# ETHSW register map
Registers are 32-bit, read-only, no defined reset value unless marked. A register's access mark holds for its fields unless they carry their own. Addresses are absolute; registers are grouped by the start of their names; [hi:lo] are bit positions; {n}, {i} and the like mark numbered series.

## etherStatsOversizePkts
{0x440508BC+0x400*i} etherStatsOversizePkts_P{i} (i=0..4)

## etherStatsPkts64Octets
{0x440508C0+0x400*i} etherStatsPkts64Octets_P{i} (i=0..4)

## etherStatsPkts65to127Octets
{0x440508C4+0x400*i} etherStatsPkts65to127Octets_P{i} (i=0..4)

## etherStatsPkts128to255Octets
{0x440508C8+0x400*i} etherStatsPkts128to255Octets_P{i} (i=0..4)

## etherStatsPkts256to511Octets
{0x440508CC+0x400*i} etherStatsPkts256to511Octets_P{i} (i=0..4)

## etherStatsPkts512to1023Octets
{0x440508D0+0x400*i} etherStatsPkts512to1023Octets_P{i} (i=0..4)

## etherStatsPkts1024to1518Octets
{0x440508D4+0x400*i} etherStatsPkts1024to1518Octets_P{i} (i=0..4)

## etherStatsPkts1519toXOctets
{0x440508D8+0x400*i} etherStatsPkts1519toXOctets_P{i} (i=0..4)

## etherStatsJabbers
{0x440508DC+0x400*i} etherStatsJabbers_P{i} (i=0..4)

## etherStatsFragments
{0x440508E0+0x400*i} etherStatsFragments_P{i} (i=0..4)

## VLANReceivedOK
{0x440508E8+0x400*i} VLANReceivedOK_P{i} (i=0..4)

## VLANTransmittedOK
{0x440508F4+0x400*i} VLANTransmittedOK_P{i} (i=0..4)

## FramesRetransmitted
{0x440508F8+0x400*i} FramesRetransmitted_P{i} (i=0..4)

## STATS
{0x44050900+0x400*i} STATS_HIWORD_P{i} (i=0..4)
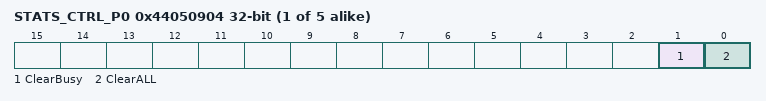
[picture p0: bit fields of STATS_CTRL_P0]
{0x44050904+0x400*i} STATS_CTRL_P{i} access not given (i=0..4)
  [1] ClearBusy, [0] ClearALL
{0x44050908+0x400*i} STATS_CLEAR_VALUELO_P{i} (i=0..4)
{0x4405090C+0x400*i} STATS_CLEAR_VALUEHI_P{i} (i=0..4)

## aDeferred
{0x44050910+0x400*i} aDeferred_P{i} (i=0..4)

## aMultipleCollisions
{0x44050914+0x400*i} aMultipleCollisions_P{i} (i=0..4)

## aSingleCollisions
{0x44050918+0x400*i} aSingleCollisions_P{i} (i=0..4)

## aLateCollisions
{0x4405091C+0x400*i} aLateCollisions_P{i} (i=0..4)

## aExcessiveCollisions
{0x44050920+0x400*i} aExcessiveCollisions_P{i} (i=0..4)

## aCarrierSenseErrors
{0x44050924+0x400*i} aCarrierSenseErrors_P{i} (i=0..4)

## DLR
0x44053C08 DLR_ETH_TYP access not given
  [15:0] DLR_ETH_TYP
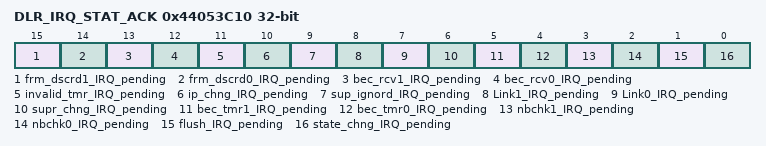
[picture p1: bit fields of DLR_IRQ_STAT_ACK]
0x44053C10 DLR_IRQ_STAT_ACK access not given
  [15] frm_dscrd1_IRQ_pending, [14] frm_dscrd0_IRQ_pending, [13] bec_rcv1_IRQ_pending, [12] bec_rcv0_IRQ_pending, [11] invalid_tmr_IRQ_pending, [10] ip_chng_IRQ_pending, [9] sup_ignord_IRQ_pending, [8] Link1_IRQ_pending, [7] Link0_IRQ_pending, [6] supr_chng_IRQ_pending, [5] bec_tmr1_IRQ_pending, [4] bec_tmr0_IRQ_pending, [3] nbchk1_IRQ_pending, [2] nbchk0_IRQ_pending, [1] flush_IRQ_pending, [0] state_chng_IRQ_pending
0x44053C58 DLR_DSTlo access not given
  [31:0] DLR_DST
0x44053C5C DLR_DSThi access not given
  [15:0] DLR_DST

## IRQ
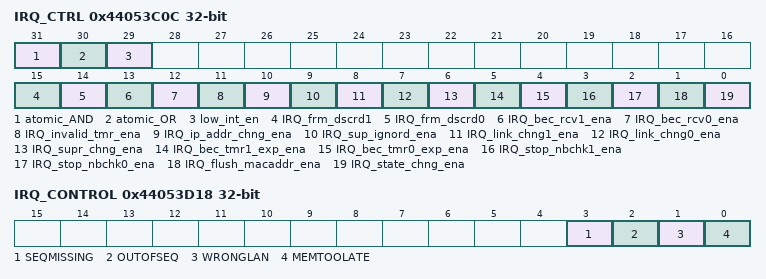
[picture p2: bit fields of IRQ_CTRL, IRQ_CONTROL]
0x44053C0C IRQ_CTRL access not given
  [31] atomic_AND, [30] atomic_OR, [29] low_int_en, [15] IRQ_frm_dscrd1, [14] IRQ_frm_dscrd0, [13] IRQ_bec_rcv1_ena, [12] IRQ_bec_rcv0_ena, [11] IRQ_invalid_tmr_ena, [10] IRQ_ip_addr_chng_ena, [9] IRQ_sup_ignord_ena, [8] IRQ_link_chng1_ena, [7] IRQ_link_chng0_ena, [6] IRQ_supr_chng_ena, [5] IRQ_bec_tmr1_exp_ena, [4] IRQ_bec_tmr0_exp_ena, [3] IRQ_stop_nbchk1_ena, [2] IRQ_stop_nbchk0_ena, [1] IRQ_flush_macaddr_ena, [0] IRQ_state_chng_ena
0x44053D18 IRQ_CONTROL access not given
  [3] SEQMISSING, [2] OUTOFSEQ, [1] WRONGLAN, [0] MEMTOOLATE
